# CH32X315 register map
Vendor: WCH Ltd.; File version: 1.1
CH32X315 View File
Registers are 32-bit, read-write, reset 0x0 unless marked. A register's access mark holds for its fields unless they carry their own. Offsets are from the block's base; lines under a group give offsets from that group; [hi:lo] are bit positions; {n}, {i} and the like mark numbered series; 'fields as' and 'values as' point back to an identical list; <NAME> marks a mode.

## Memory map
0x1FFFF7E0 ESIG size 0x200 — ESIG configuration
0x40000000 TIM2 size 0x400 — General purpose timer
0x40000400 TIM3 size 0x400
0x40000800 TIM4 size 0x400 — General purpose timer
0x40002800 RTC size 0x400 — Real time clock
0x40002C00 WWDG size 0x400 — Window watchdog
0x40003000 IWDG size 0x400 — Independent watchdog
0x40003800 SPI2 size 0x400
0x40003C00 SPI3 size 0x400
0x40004400 USART2 size 0x400
0x40004800 USART3 size 0x400
0x40004C00 UART4 size 0x400
0x40005400 I2C1 size 0x400 — Inter integrated circuit
0x40005800 I2C2 size 0x400
0x40007000 PWR size 0x400 — Power control
0x40010000 AFIO size 0x400 — Alternate function I/O
0x40010400 EXTI size 0x400
0x40010800 GPIOA size 0x400 — General purpose I/O
0x40010C00 GPIOB size 0x400
0x40011000 GPIOC size 0x400
0x40011400 GPIOD size 0x400
0x40012400 ADC1 size 0x400 — Analog to digital converter
0x40012800 ADC2 size 0x400
0x40012C00 TIM1 size 0x400 — Advanced timer
0x40013000 SPI1 size 0x400 — Serial peripheral interface
0x40013800 USART1 size 0x400 — Universal synchronous asynchronous receiver transmitter
0x40013C00 ADC3 size 0x400
0x40014000 ADC4 size 0x400
0x40020000 DMA1 size 0x400 — DMA1 controller
0x40021000 RCC size 0x400 — Reset and clock control
0x40022000 FLASH size 0x400
0x40023000 CRC size 0x400 — CRC calculation unit
0x40023400 ARGB size 0x400
0x40024400 USBPD size 0x400 — USBPD configuration
0x40030000 USBHS size 0x400 — USB register
0x40038000 USBSS size 0x400 — USB3.0 ultra-high speed host /device controller
0xE000E000 PFIC size 0x1000 — Programmable Fast Interrupt Controller
0xE000F000 STK size 0xFFF — SysTick

## Interrupts
16 WWDG — Window Watchdog interrupt
17 EXTI15_8 (EXTI) — EXTI Line[15:8] interrupts
18 FLASH — Flash global interrupt
19 RCC — RCC global interrupt
20 EXTI7_0 (EXTI) — EXTI Line[7:0] interrupt
21 SPI2 — SPI2 event interrupt
{n+21} DMA1_CH{n} (DMA1) (n=1..11) — DMA1 Channel{n} global interrupt
33 USART2 — USART2 global interrupt
34 I2C1_EV (I2C1) — I2C1 event interrupt
35 I2C1_ER (I2C1) — I2C1 error interrupt
36 USART1 — USART1 global interrupt
37 SPI1 — SPI1 global interrupt
38 TIM1_UP (TIM1) — TIM1 Update interrupt
39 TIM1_CC (TIM1) — TIM1 Capture Compare interrupt
40 TIM1_TRG_COM (TIM1) — TIM1 Trigger and Commutation interrupts
41 TIM1_BRK (TIM1) — TIM1 Break interrupt
42 TIM2 — TIM2 global interrupt
43 I2C2_EV (I2C2) — I2C2 event interrupt
44 I2C2_ER (I2C2) — I2C2 error interrupt
45 USBPD — USBPD global interrupt
46 USBPDWakeUP (USBPD) — USBPD_WKUP global interrupt
47 ARGB — ARGB global interrupts
48 TIM3 — TIM3 global interrupt
49 TIM4 — TIM4 global interrupt
50 SPI3 — SPI3 event interrupt
51 USART3 — USART3 global interrupt
52 UART4 — UART4 global interrupt
53 USBSS — USBSS global interrupt
54 USBSS_LINK (USBSS) — USBSS LINK interrupt
55 USBHS — USBHS global interrupt
56 USBHSWakeUP (USBHS) — USBHS Wakeup interrupt
57 USBSSWakeUP (USBSS) — USBSS wake-up interrupt
58 PVD (PWR) — PVD through EXTI line detection interrupt
59 ADC1 — ADC1 global interrupt
60 ADC2 — ADC2 global interrupt
61 ADC3 — ADC3 global interrupt
62 RTCAlarm (RTC) — RTC Alarms through EXTI line interrupt
63 RTC — RTC global interrupt
64 USARTWakeUP (USART1) — USART wakeup global interrupt
65 ADC4 — ADC4 global interrupt

## PWR — Power control
Base 0x40007000
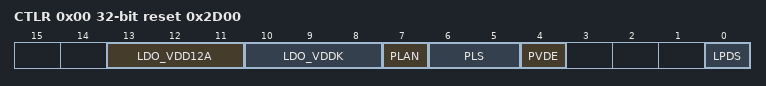
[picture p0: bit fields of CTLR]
0x00 CTLR reset 0x2D00 — Power control register (PWR_CTRL)
  [13:11] LDO_VDD12A — VDD12A voltage regulation position
  [10:8] LDO_VDDK — VDDK voltage regulation position
  [7] PLAN — power conditioning pre-positioning enable bit
  [6:5] PLS — PVD Level Selection
  [4] PVDE — Power Voltage Detector Enable
  [0] LPDS — Low Power Deep Sleep
0x04 CSR ro — Power control register (PWR_CSR)
  [0] PVDO — PVD Output
